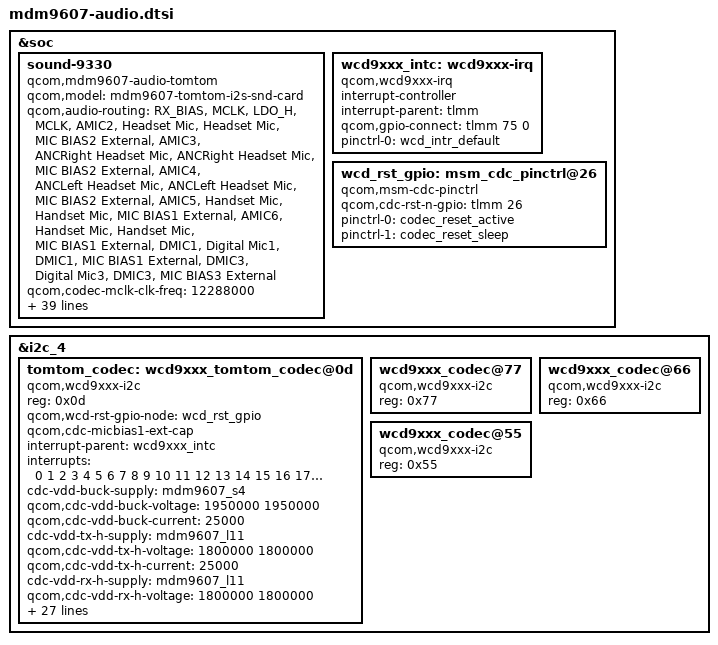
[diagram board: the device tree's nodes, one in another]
#include "mdm9607-audio-lpass.dtsi"

&soc {
	sound-9330 {
		compatible = "qcom,mdm9607-audio-tomtom";
		qcom,model = "mdm9607-tomtom-i2s-snd-card";

		qcom,audio-routing =
			"RX_BIAS", "MCLK",
			"LDO_H", "MCLK",
			"AMIC2", "Headset Mic",
			"Headset Mic", "MIC BIAS2 External",
			"AMIC3", "ANCRight Headset Mic",
			"ANCRight Headset Mic", "MIC BIAS2 External",
			"AMIC4", "ANCLeft Headset Mic",
			"ANCLeft Headset Mic", "MIC BIAS2 External",
			"AMIC5", "Handset Mic",
			"Handset Mic", "MIC BIAS1 External",
			"AMIC6", "Handset Mic",
			"Handset Mic", "MIC BIAS1 External",
			"DMIC1", "Digital Mic1",
			"DMIC1", "MIC BIAS1 External",
			"DMIC3", "Digital Mic3",
			"DMIC3", "MIC BIAS3 External";

		qcom,codec-mclk-clk-freq = <12288000>;
		qcom,prim_mi2s_aux_master = <&prim_master>;
		qcom,sec_mi2s_aux_master = <&sec_master>;
		asoc-platform = <&pcm0>, <&pcm1>, <&voip>, <&voice>,
				<&loopback>, <&hostless>, <&afe>, <&routing>,
				<&pcm_dtmf>, <&host_pcm>, <&compress>;
		asoc-platform-names = "msm-pcm-dsp.0", "msm-pcm-dsp.1",
				"msm-voip-dsp", "msm-pcm-voice",
				"msm-pcm-loopback", "msm-pcm-hostless",
				"msm-pcm-afe", "msm-pcm-routing",
				"msm-pcm-dtmf", "msm-voice-host-pcm",
				"msm-compress-dsp";
		asoc-cpu = <&dai_pri_auxpcm_rx>, <&dai_pri_auxpcm_tx>,
				<&dai_sec_auxpcm_rx>, <&dai_sec_auxpcm_tx>,
				<&mi2s_prim_rx>, <&mi2s_prim_tx>,
				<&mi2s_sec_rx>, <&mi2s_sec_tx>, <&dtmf_tx>,
				<&rx_capture_tx>, <&rx_playback_rx>,
				<&tx_capture_tx>, <&tx_playback_rx>,
				<&afe_pcm_rx>, <&afe_pcm_tx>, <&afe_proxy_rx>,
				<&afe_proxy_tx>, <&incall_record_rx>,
				<&incall_record_tx>, <&incall_music_rx>,
				<&dai_pri_tdm_rx_0>, <&dai_pri_tdm_tx_0>,
				<&dai_sec_tdm_rx_0>, <&dai_sec_tdm_tx_0>;
		asoc-cpu-names = "msm-dai-q6-auxpcm.1", "msm-dai-q6-auxpcm.2",
				"msm-dai-q6-auxpcm.3", "msm-dai-q6-auxpcm.4",
				"msm-dai-q6-mi2s.0", "msm-dai-q6-mi2s.1",
				"msm-dai-q6-mi2s.2", "msm-dai-q6-mi2s.3",
				"msm-dai-stub-dev.4", "msm-dai-stub-dev.5",
				"msm-dai-stub-dev.6", "msm-dai-stub-dev.7",
				"msm-dai-stub-dev.8", "msm-dai-q6-dev.224",
				"msm-dai-q6-dev.225", "msm-dai-q6-dev.241",
				"msm-dai-q6-dev.240", "msm-dai-q6-dev.32771",
				"msm-dai-q6-dev.32772", "msm-dai-q6-dev.32773",
				"msm-dai-q6-tdm.36864", "msm-dai-q6-tdm.36865",
				"msm-dai-q6-tdm.36880", "msm-dai-q6-tdm.36881";
		asoc-codec = <&stub_codec>, <&tomtom_codec>;
		asoc-codec-names = "msm-stub-codec.1", "tomtom_codec";
		qcom,msm_audio_ssr_devs = <&audio_apr>, <&q6core>, <&tomtom_codec>;
	};

	wcd9xxx_intc: wcd9xxx-irq {
		status = "ok";
		compatible = "qcom,wcd9xxx-irq";
		interrupt-controller;
		#interrupt-cells = <1>;
		interrupt-parent = <&tlmm>;
		qcom,gpio-connect = <&tlmm 75 0>;
		pinctrl-names = "default";
		pinctrl-0 = <&wcd_intr_default>;
	};

	wcd_rst_gpio: msm_cdc_pinctrl@26 {
		compatible = "qcom,msm-cdc-pinctrl";
		qcom,cdc-rst-n-gpio = <&tlmm 26 0>;
		pinctrl-names = "aud_active", "aud_sleep";
		pinctrl-0 = <&codec_reset_active>;
		pinctrl-1 = <&codec_reset_sleep>;
	};
};

&i2c_4 {
	status = "ok";
	tomtom_codec: wcd9xxx_tomtom_codec@0d {
		compatible = "qcom,wcd9xxx-i2c";
		reg = <0x0d>;

		qcom,wcd-rst-gpio-node = <&wcd_rst_gpio>;

		qcom,cdc-micbias1-ext-cap;

		interrupt-parent = <&wcd9xxx_intc>;
		interrupts = <0 1 2 3 4 5 6 7 8 9 10 11 12 13 14 15
			16 17 18 19 20 21 22 23 24 25 26 27 28>;
		cdc-vdd-buck-supply = <&mdm9607_s4>;
		qcom,cdc-vdd-buck-voltage = <1950000 1950000>;
		qcom,cdc-vdd-buck-current = <25000>;

		cdc-vdd-tx-h-supply = <&mdm9607_l11>;
		qcom,cdc-vdd-tx-h-voltage = <1800000 1800000>;
		qcom,cdc-vdd-tx-h-current = <25000>;

		cdc-vdd-rx-h-supply = <&mdm9607_l11>;
		qcom,cdc-vdd-rx-h-voltage = <1800000 1800000>;
		qcom,cdc-vdd-rx-h-current = <25000>;

		cdc-vddpx-1-supply = <&mdm9607_l11>;
		qcom,cdc-vddpx-1-voltage = <1800000 1800000>;
		qcom,cdc-vddpx-1-current = <10000>;

		cdc-vdd-a-1p2v-supply = <&mdm9607_l9>;
		qcom,cdc-vdd-a-1p2v-voltage = <1225000 1225000>;
		qcom,cdc-vdd-a-1p2v-current = <10000>;

		cdc-vddcx-1-supply = <&mdm9607_l9>;
		qcom,cdc-vddcx-1-voltage = <1225000 1225000>;
		qcom,cdc-vddcx-1-current = <10000>;

		cdc-vddcx-2-supply = <&mdm9607_l9>;
		qcom,cdc-vddcx-2-voltage = <1225000 1225000>;
		qcom,cdc-vddcx-2-current = <10000>;

		qcom,cdc-static-supplies = "cdc-vdd-buck",
					   "cdc-vdd-tx-h",
					   "cdc-vdd-rx-h",
					   "cdc-vddpx-1",
					   "cdc-vdd-a-1p2v",
					   "cdc-vddcx-1",
					   "cdc-vddcx-2";

		qcom,cdc-micbias-ldoh-v = <0x3>;
		qcom,cdc-micbias-cfilt1-mv = <1800>;
		qcom,cdc-micbias-cfilt2-mv = <2700>;
		qcom,cdc-micbias-cfilt3-mv = <1800>;
		qcom,cdc-micbias1-cfilt-sel = <0x0>;
		qcom,cdc-micbias2-cfilt-sel = <0x1>;
		qcom,cdc-micbias3-cfilt-sel = <0x2>;
		qcom,cdc-micbias4-cfilt-sel = <0x2>;
		qcom,cdc-mclk-clk-rate = <12288000>;
		qcom,cdc-dmic-sample-rate = <4800000>;
		qcom,cdc-variant = "WCD9330";
	};

	wcd9xxx_codec@77 {
		compatible = "qcom,wcd9xxx-i2c";
		reg = <0x77>;
	};

	wcd9xxx_codec@66 {
		compatible = "qcom,wcd9xxx-i2c";
		reg = <0x66>;
	};

	wcd9xxx_codec@55 {
		compatible = "qcom,wcd9xxx-i2c";
		reg = <0x55>;
	};

};

